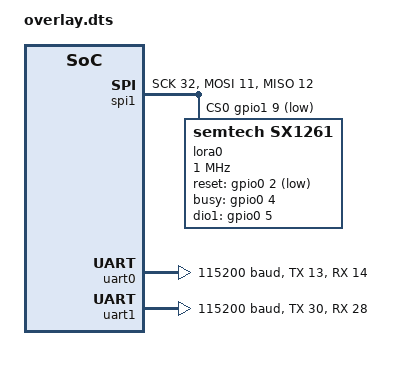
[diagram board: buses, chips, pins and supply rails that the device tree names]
// https://github.com/zephyrproject-rtos/zephyr/issues/27915
&spi1 {
	compatible = "nordic,nrf-spi";
	status = "okay";
	// draeger module (new):
	sck-pin = <32>;
	mosi-pin = <11>;
	miso-pin = <12>;
	cs-gpios = <&gpio1 9 GPIO_ACTIVE_LOW>;
	// draeger module (telit):
//	sck-pin = <6>;
//	mosi-pin = <14>;
//	miso-pin = <5>;
//	cs-gpios = <&gpio0 16 GPIO_ACTIVE_LOW>;
    // eval board:
//	sck-pin = <25>;
//	mosi-pin = <23>;
//	miso-pin = <24>;
//	cs-gpios = <&gpio0 18 GPIO_ACTIVE_LOW>;
	lora0: sx1261@0 {
		compatible = "semtech,sx1261";
		reg = <0>;
		label = "lora0";
		// -- draeger module (new):
		reset-gpios = <&gpio0 2 GPIO_ACTIVE_LOW>;
		busy-gpios = <&gpio0 4 GPIO_ACTIVE_HIGH>;
		dio1-gpios = <&gpio0 5 GPIO_ACTIVE_HIGH>;
		// -- draeger module (telit):
//		reset-gpios = <&gpio0 31 GPIO_ACTIVE_LOW>;
//		// busy pin: 25 on first hw version, must be changed to 22 and resoldered on hw1
//		busy-gpios = <&gpio0 22 GPIO_ACTIVE_HIGH>;
//		//busy-gpios = <&gpio0 25 GPIO_ACTIVE_HIGH>;
//		dio1-gpios = <&gpio0 8 GPIO_ACTIVE_HIGH>;
		// -- eval board:
//		reset-gpios = <&gpio0 3 GPIO_ACTIVE_LOW>;
//		busy-gpios = <&gpio0 14 GPIO_ACTIVE_HIGH>;
//		dio1-gpios = <&gpio0 16 GPIO_ACTIVE_HIGH>;
        // --
		spi-max-frequency = <1000000>;
		status = "okay";
		dio2-tx-enable;
	};
};

&uart0 {
	status = "okay";
	compatible = "nordic,nrf-uarte";
	current-speed = <115200>;
	// draeger module (new):
	tx-pin = <13>;
	rx-pin = <14>;
	rts-pin = <16>;
	cts-pin = <17>;
	// draeger module (telit):
//	tx-pin = <17>;
//	rx-pin = <11>;
//	rts-pin = <7>;
//	cts-pin = <12>;
	// eval board:
//	tx-pin = <6>;
//	rx-pin = <8>;
//	rts-pin = <5>;
//	cts-pin = <7>;
};
&uart1 {
	status = "okay";
	compatible = "nordic,nrf-uarte";
	current-speed = <115200>;
	// draeger module (new):
	tx-pin = <30>;
	rx-pin = <28>;
};
